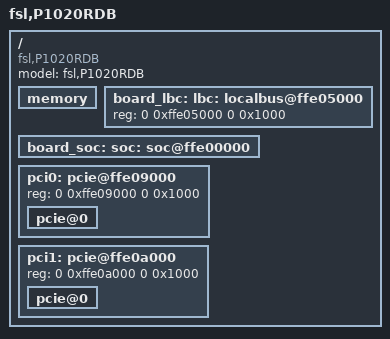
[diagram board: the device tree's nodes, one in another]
// SPDX-License-Identifier: GPL-2.0-or-later
/*
 * P1020 RDB Device Tree Source
 *
 * Copyright 2009-2011 Freescale Semiconductor Inc.
 */

/include/ "p1020si-pre.dtsi"
/ {
	model = "fsl,P1020RDB";
	compatible = "fsl,P1020RDB";

	memory {
		device_type = "memory";
	};

	board_lbc: lbc: localbus@ffe05000 {
		reg = <0 0xffe05000 0 0x1000>;

		/* NOR, NAND Flashes and Vitesse 5 port L2 switch */
		ranges = <0x0 0x0 0x0 0xef000000 0x01000000
			  0x1 0x0 0x0 0xffa00000 0x00040000
			  0x2 0x0 0x0 0xffb00000 0x00020000>;
	};

	board_soc: soc: soc@ffe00000 {
		ranges = <0x0 0x0 0xffe00000 0x100000>;
	};

	pci0: pcie@ffe09000 {
		ranges = <0x2000000 0x0 0xa0000000 0 0xa0000000 0x0 0x20000000
			  0x1000000 0x0 0x00000000 0 0xffc10000 0x0 0x10000>;
		reg = <0 0xffe09000 0 0x1000>;
		pcie@0 {
			ranges = <0x2000000 0x0 0xa0000000
				  0x2000000 0x0 0xa0000000
				  0x0 0x20000000

				  0x1000000 0x0 0x0
				  0x1000000 0x0 0x0
				  0x0 0x100000>;
		};
	};

	pci1: pcie@ffe0a000 {
		reg = <0 0xffe0a000 0 0x1000>;
		ranges = <0x2000000 0x0 0x80000000 0 0x80000000 0x0 0x20000000
			  0x1000000 0x0 0x00000000 0 0xffc00000 0x0 0x10000>;
		pcie@0 {
			ranges = <0x2000000 0x0 0x80000000
				  0x2000000 0x0 0x80000000
				  0x0 0x20000000

				  0x1000000 0x0 0x0
				  0x1000000 0x0 0x0
				  0x0 0x100000>;
		};
	};
};

/include/ "p1020rdb.dtsi"
/include/ "p1020si-post.dtsi"
